CM_ "AUTOGENERATED FILE, DO NOT EDIT";

CM_ "Imported file _honda_common.dbc starts here";
BO_ 304 GAS_PEDAL_2: 8 PCM
 SG_ ENGINE_TORQUE_ESTIMATE : 7|16@0- (1,0) [-1000|1000] "Nm" EON
 SG_ ENGINE_TORQUE_REQUEST : 23|16@0- (1,0) [-1000|1000] "Nm" EON
 SG_ CAR_GAS : 39|8@0+ (1,0) [0|255] "" EON
 SG_ COUNTER : 61|2@0+ (1,0) [0|3] "" EON
 SG_ CHECKSUM : 59|4@0+ (1,0) [0|15] "" EON

BO_ 316 GAS_PEDAL: 8 PCM
 SG_ CAR_GAS : 39|8@0+ (1,0) [0|255] "" EON
 SG_ COUNTER : 61|2@0+ (1,0) [0|3] "" EON
 SG_ CHECKSUM : 59|4@0+ (1,0) [0|15] "" EON

BO_ 344 ENGINE_DATA: 8 PCM
 SG_ XMISSION_SPEED : 7|16@0+ (0.01,0) [0|250] "kph" EON
 SG_ ENGINE_RPM : 23|16@0+ (1,0) [0|15000] "rpm" EON
 SG_ XMISSION_SPEED2 : 39|16@0+ (0.01,0) [0|250] "kph" EON
 SG_ ODOMETER : 55|8@0+ (10,0) [0|2550] "m" XXX
 SG_ COUNTER : 61|2@0+ (1,0) [0|3] "" EON
 SG_ CHECKSUM : 59|4@0+ (1,0) [0|15] "" EON

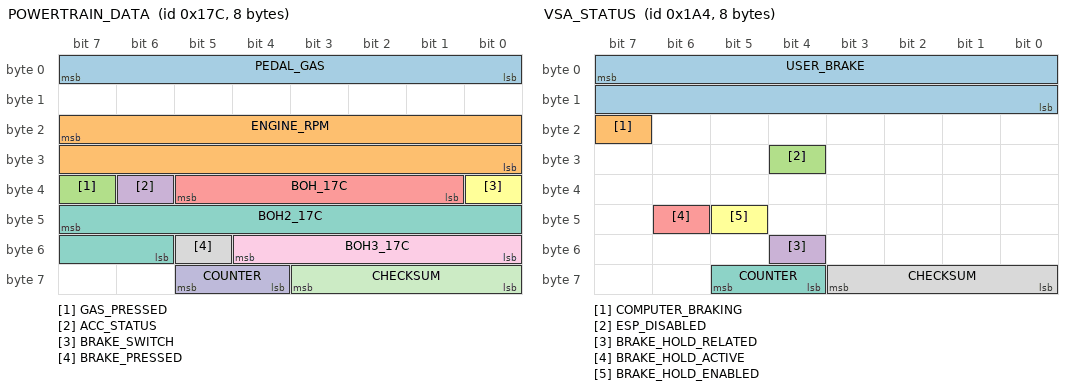
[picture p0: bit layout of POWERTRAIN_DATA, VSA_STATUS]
BO_ 380 POWERTRAIN_DATA: 8 PCM
 SG_ PEDAL_GAS : 7|8@0+ (1,0) [0|255] "" EON
 SG_ ENGINE_RPM : 23|16@0+ (1,0) [0|15000] "rpm" EON
 SG_ GAS_PRESSED : 39|1@0+ (1,0) [0|1] "" EON
 SG_ ACC_STATUS : 38|1@0+ (1,0) [0|1] "" EON
 SG_ BOH_17C : 37|5@0+ (1,0) [0|1] "" EON
 SG_ BRAKE_SWITCH : 32|1@0+ (1,0) [0|1] "" EON
 SG_ BOH2_17C : 47|10@0+ (1,0) [0|1] "" EON
 SG_ BRAKE_PRESSED : 53|1@0+ (1,0) [0|1] "" EON
 SG_ BOH3_17C : 52|5@0+ (1,0) [0|1] "" EON
 SG_ COUNTER : 61|2@0+ (1,0) [0|3] "" EON
 SG_ CHECKSUM : 59|4@0+ (1,0) [0|15] "" EON

BO_ 420 VSA_STATUS: 8 VSA
 SG_ USER_BRAKE : 7|16@0+ (0.015625,-1.609375) [0|1000] "" EON
 SG_ COMPUTER_BRAKING : 23|1@0+ (1,0) [0|1] "" EON
 SG_ ESP_DISABLED : 28|1@0+ (1,0) [0|1] "" EON
 SG_ BRAKE_HOLD_RELATED : 52|1@0+ (1,0) [0|1] "" XXX
 SG_ BRAKE_HOLD_ACTIVE : 46|1@0+ (1,0) [0|1] "" EON
 SG_ BRAKE_HOLD_ENABLED : 45|1@0+ (1,0) [0|1] "" EON
 SG_ COUNTER : 61|2@0+ (1,0) [0|3] "" EON
 SG_ CHECKSUM : 59|4@0+ (1,0) [0|15] "" EON

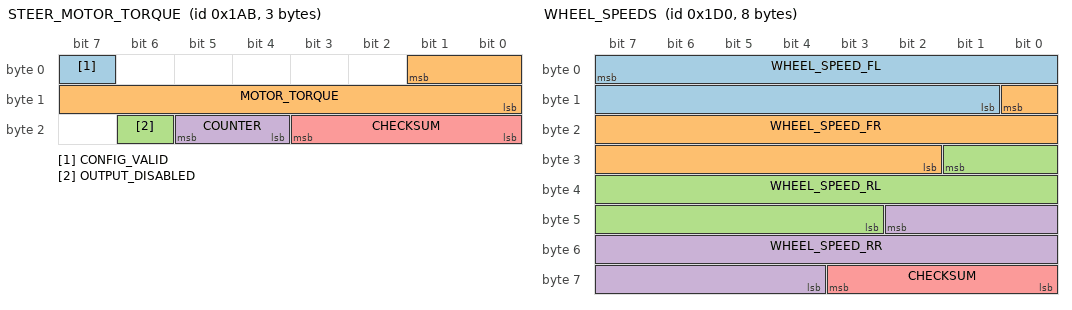
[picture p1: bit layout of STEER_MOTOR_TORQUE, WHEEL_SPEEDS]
BO_ 427 STEER_MOTOR_TORQUE: 3 EPS
 SG_ CONFIG_VALID : 7|1@0+ (1,0) [0|1] "" EON
 SG_ MOTOR_TORQUE : 1|10@0+ (1,0) [0|256] "" EON
 SG_ OUTPUT_DISABLED : 22|1@0+ (1,0) [0|1] "" EON
 SG_ COUNTER : 21|2@0+ (1,0) [0|3] "" EON
 SG_ CHECKSUM : 19|4@0+ (1,0) [0|15] "" EON

BO_ 464 WHEEL_SPEEDS: 8 VSA
 SG_ WHEEL_SPEED_FL : 7|15@0+ (0.01,0) [0|250] "kph" EON
 SG_ WHEEL_SPEED_FR : 8|15@0+ (0.01,0) [0|250] "kph" EON
 SG_ WHEEL_SPEED_RL : 25|15@0+ (0.01,0) [0|250] "kph" EON
 SG_ WHEEL_SPEED_RR : 42|15@0+ (0.01,0) [0|250] "kph" EON
 SG_ CHECKSUM : 59|4@0+ (1,0) [0|3] "" EON

BO_ 490 VEHICLE_DYNAMICS: 8 VSA
 SG_ LAT_ACCEL : 7|16@0- (0.0015,0) [-20|20] "m/s2" EON
 SG_ LONG_ACCEL : 23|16@0- (0.0015,0) [-20|20] "m/s2" EON
 SG_ COUNTER : 61|2@0+ (1,0) [0|3] "" EON
 SG_ CHECKSUM : 59|4@0+ (1,0) [0|3] "" EON

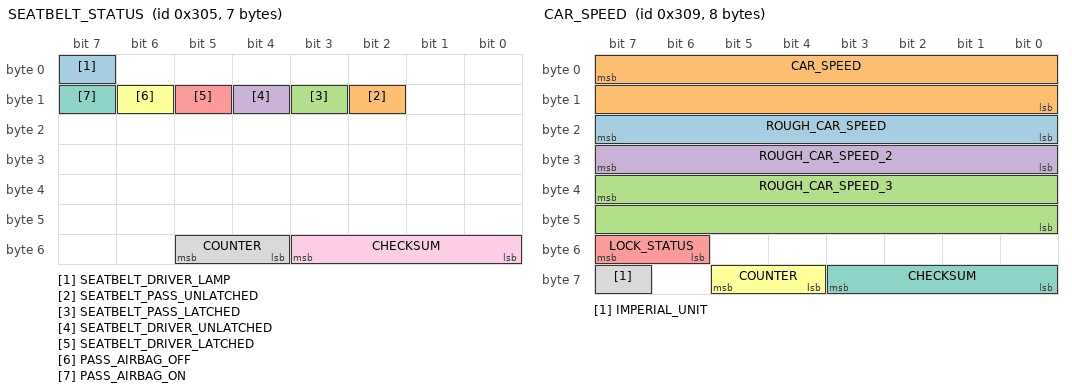
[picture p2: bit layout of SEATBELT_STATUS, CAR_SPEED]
BO_ 773 SEATBELT_STATUS: 7 BDY
 SG_ SEATBELT_DRIVER_LAMP : 7|1@0+ (1,0) [0|1] "" EON
 SG_ SEATBELT_PASS_UNLATCHED : 10|1@0+ (1,0) [0|1] "" EON
 SG_ SEATBELT_PASS_LATCHED : 11|1@0+ (1,0) [0|1] "" EON
 SG_ SEATBELT_DRIVER_UNLATCHED : 12|1@0+ (1,0) [0|1] "" EON
 SG_ SEATBELT_DRIVER_LATCHED : 13|1@0+ (1,0) [0|1] "" EON
 SG_ PASS_AIRBAG_OFF : 14|1@0+ (1,0) [0|1] "" EON
 SG_ PASS_AIRBAG_ON : 15|1@0+ (1,0) [0|1] "" EON
 SG_ COUNTER : 53|2@0+ (1,0) [0|3] "" EON
 SG_ CHECKSUM : 51|4@0+ (1,0) [0|3] "" EON

BO_ 777 CAR_SPEED: 8 PCM
 SG_ ROUGH_CAR_SPEED : 23|8@0+ (1,0) [0|255] "mph" XXX
 SG_ CAR_SPEED : 7|16@0+ (0.01,0) [0|65535] "kph" XXX
 SG_ ROUGH_CAR_SPEED_3 : 39|16@0+ (0.01,0) [0|65535] "kph" XXX
 SG_ ROUGH_CAR_SPEED_2 : 31|8@0+ (1,0) [0|255] "mph" XXX
 SG_ LOCK_STATUS : 55|2@0+ (1,0) [0|255] "" XXX
 SG_ COUNTER : 61|2@0+ (1,0) [0|3] "" XXX
 SG_ CHECKSUM : 59|4@0+ (1,0) [0|15] "" XXX
 SG_ IMPERIAL_UNIT : 63|1@0+ (1,0) [0|1] "" XXX

BO_ 780 ACC_HUD: 8 ADAS
 SG_ PCM_SPEED : 7|16@0+ (0.01,0) [0|250] "kph" BDY
 SG_ PCM_GAS : 23|8@0+ (1,0) [0|127] "" BDY
 SG_ CRUISE_SPEED : 31|8@0+ (1,0) [0|255] "kph" BDY
 SG_ DTC_MODE : 39|1@0+ (1,0) [0|1] "" BDY
 SG_ BOH : 38|1@0+ (1,0) [0|1] "" BDY
 SG_ ACC_PROBLEM : 37|1@0+ (1,0) [0|1] "" BDY
 SG_ FCM_OFF : 35|1@0+ (1,0) [0|1] "" BDY
 SG_ FCM_OFF_2 : 36|1@0+ (1,0) [0|1] "" BDY
 SG_ FCM_PROBLEM : 34|1@0+ (1,0) [0|1] "" BDY
 SG_ RADAR_OBSTRUCTED : 33|1@0+ (1,0) [0|1] "" BDY
 SG_ ENABLE_MINI_CAR : 32|1@0+ (1,0) [0|1] "" BDY
 SG_ HUD_DISTANCE : 47|2@0+ (1,0) [0|3] "" BDY
 SG_ HUD_LEAD : 45|2@0+ (1,0) [0|3] "" BDY
 SG_ BOH_3 : 43|1@0+ (1,0) [0|3] "" BDY
 SG_ BOH_4 : 42|1@0+ (1,0) [0|3] "" BDY
 SG_ BOH_5 : 41|1@0+ (1,0) [0|3] "" BDY
 SG_ CRUISE_CONTROL_LABEL : 40|1@0+ (1,0) [0|3] "" BDY
 SG_ SET_ME_X01_2 : 55|1@0+ (1,0) [0|1] "" BDY
 SG_ IMPERIAL_UNIT : 54|1@0+ (1,0) [0|1] "" BDY
 SG_ ACC_ON : 52|1@0+ (1,0) [0|1] "" BDY
 SG_ CHIME : 51|3@0+ (1,0) [0|1] "" BDY
 SG_ SET_ME_X01 : 48|1@0+ (1,0) [0|1] "" BDY
 SG_ ICONS : 63|2@0+ (1,0) [0|1] "" BDY
 SG_ COUNTER : 61|2@0+ (1,0) [0|3] "" BDY
 SG_ CHECKSUM : 59|4@0+ (1,0) [0|3] "" BDY

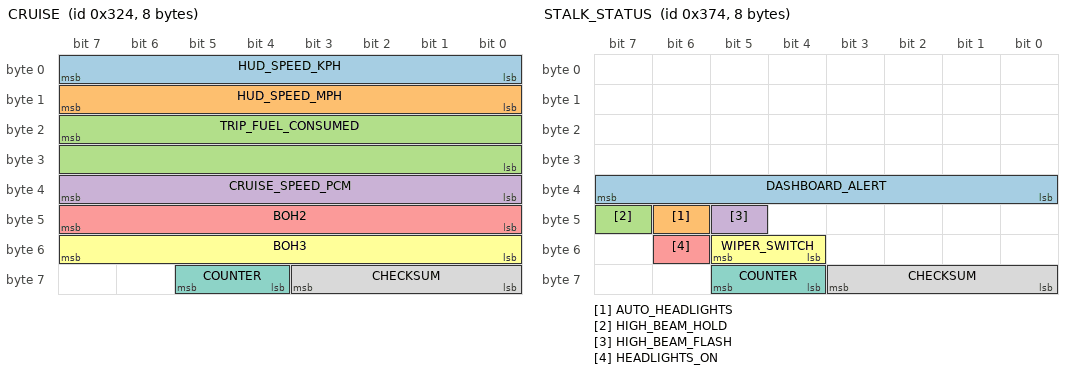
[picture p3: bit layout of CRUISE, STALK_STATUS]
BO_ 804 CRUISE: 8 PCM
 SG_ HUD_SPEED_KPH : 7|8@0+ (1,0) [0|255] "kph" EON
 SG_ HUD_SPEED_MPH : 15|8@0+ (1,0) [0|255] "mph" EON
 SG_ TRIP_FUEL_CONSUMED : 23|16@0+ (1,0) [0|255] "" EON
 SG_ CRUISE_SPEED_PCM : 39|8@0+ (1,0) [0|255] "" EON
 SG_ BOH2 : 47|8@0- (1,0) [0|255] "" EON
 SG_ BOH3 : 55|8@0+ (1,0) [0|255] "" EON
 SG_ COUNTER : 61|2@0+ (1,0) [0|3] "" EON
 SG_ CHECKSUM : 59|4@0+ (1,0) [0|15] "" EON

BO_ 884 STALK_STATUS: 8 XXX
 SG_ DASHBOARD_ALERT : 39|8@0+ (1,0) [0|255] "" EON
 SG_ AUTO_HEADLIGHTS : 46|1@0+ (1,0) [0|1] "" EON
 SG_ HIGH_BEAM_HOLD : 47|1@0+ (1,0) [0|1] "" EON
 SG_ HIGH_BEAM_FLASH : 45|1@0+ (1,0) [0|1] "" EON
 SG_ HEADLIGHTS_ON : 54|1@0+ (1,0) [0|1] "" EON
 SG_ WIPER_SWITCH : 53|2@0+ (1,0) [0|3] "" XXX
 SG_ COUNTER : 61|2@0+ (1,0) [0|3] "" EON
 SG_ CHECKSUM : 59|4@0+ (1,0) [0|15] "" EON

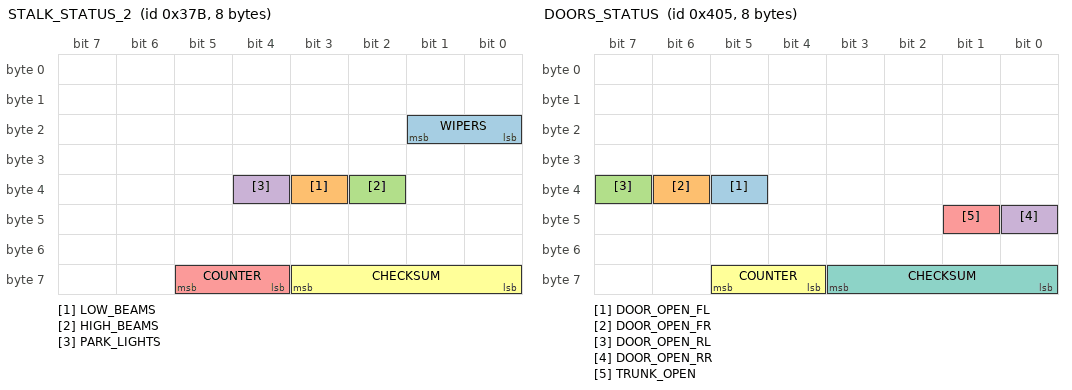
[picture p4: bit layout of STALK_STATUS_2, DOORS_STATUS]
BO_ 891 STALK_STATUS_2: 8 XXX
 SG_ WIPERS : 17|2@0+ (1,0) [0|3] "" EON
 SG_ LOW_BEAMS : 35|1@0+ (1,0) [0|1] "" XXX
 SG_ HIGH_BEAMS : 34|1@0+ (1,0) [0|1] "" XXX
 SG_ PARK_LIGHTS : 36|1@0+ (1,0) [0|1] "" XXX
 SG_ COUNTER : 61|2@0+ (1,0) [0|3] "" EON
 SG_ CHECKSUM : 59|4@0+ (1,0) [0|15] "" EON

BO_ 1029 DOORS_STATUS: 8 BDY
 SG_ DOOR_OPEN_FL : 37|1@0+ (1,0) [0|1] "" EON
 SG_ DOOR_OPEN_FR : 38|1@0+ (1,0) [0|1] "" EON
 SG_ DOOR_OPEN_RL : 39|1@0+ (1,0) [0|1] "" EON
 SG_ DOOR_OPEN_RR : 40|1@0+ (1,0) [0|1] "" EON
 SG_ TRUNK_OPEN : 41|1@0+ (1,0) [0|1] "" EON
 SG_ COUNTER : 61|2@0+ (1,0) [0|3] "" EON
 SG_ CHECKSUM : 59|4@0+ (1,0) [0|15] "" EON

CM_ SG_ 304 "Seems to be platform-agnostic";
CM_ SG_ 316 "Should exist on Nidec";
CM_ SG_ 420 BRAKE_HOLD_RELATED "On when Brake Hold engaged";
CM_ SG_ 490 LONG_ACCEL "wheel speed derivative, noisy and zero snapping";
CM_ SG_ 773 PASS_AIRBAG_ON "Might just be indicator light";
CM_ SG_ 773 PASS_AIRBAG_OFF "Might just be indicator light";
CM_ SG_ 780 CRUISE_SPEED "255 = no speed";
CM_ SG_ 780 PCM_SPEED "Used by Nidec";
CM_ SG_ 780 PCM_GAS "Used by Nidec";
CM_ SG_ 804 CRUISE_SPEED_PCM "255 = no speed";

VAL_ 780 CRUISE_SPEED 255 "no_speed" 252 "stopped";
VAL_ 780 HUD_LEAD 3 "acc_off" 2 "solid_car" 1 "dashed_car" 0 "no_car";
VAL_ 884 DASHBOARD_ALERT 0 "none" 51 "acc_problem" 55 "cmbs_problem" 75 "key_not_detected" 79 "fasten_seatbelt" 111 "lkas_problem" 131 "brake_system_problem" 132 "brake_hold_problem" 139 "tbd" 161 "door_open";
VAL_ 891 WIPERS 4 "High" 2 "Low" 0 "Off";

CM_ "Imported file _bosch_2018.dbc starts here";
BO_ 148 KINEMATICS: 8 XXX
 SG_ LAT_ACCEL : 7|10@0+ (-0.035,17.92) [-20|20] "m/s2" EON
 SG_ LONG_ACCEL : 25|10@0+ (-0.035,17.92) [-20|20] "m/s2" EON
 SG_ CHECKSUM : 59|4@0+ (1,0) [0|3] "" EON
 SG_ COUNTER : 61|2@0+ (1,0) [0|3] "" EON

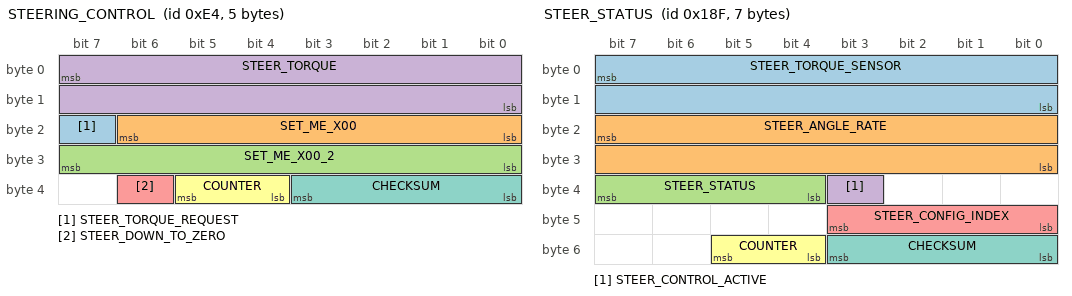
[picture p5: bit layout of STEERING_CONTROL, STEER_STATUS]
BO_ 228 STEERING_CONTROL: 5 EON
 SG_ STEER_TORQUE_REQUEST : 23|1@0+ (1,0) [0|1] "" EPS
 SG_ SET_ME_X00 : 22|7@0+ (1,0) [0|127] "" EPS
 SG_ SET_ME_X00_2 : 31|8@0+ (1,0) [0|0] "" EPS
 SG_ STEER_TORQUE : 7|16@0- (1,0) [-4096|4096] "" EPS
 SG_ STEER_DOWN_TO_ZERO : 38|1@0+ (1,0) [0|1] "" EPS
 SG_ COUNTER : 37|2@0+ (1,0) [0|3] "" EPS
 SG_ CHECKSUM : 35|4@0+ (1,0) [0|15] "" EPS

BO_ 229 BOSCH_SUPPLEMENTAL_1: 8 XXX
 SG_ SET_ME_X04 : 0|8@1+ (1,0) [0|255] "" XXX
 SG_ SET_ME_X00 : 8|8@1+ (1,0) [0|255] "" XXX
 SG_ SET_ME_X80 : 16|8@1+ (1,0) [0|255] "" XXX
 SG_ SET_ME_X10 : 24|8@1+ (1,0) [0|255] "" XXX
 SG_ COUNTER : 61|2@0+ (1,0) [0|3] "" XXX
 SG_ CHECKSUM : 59|4@0+ (1,0) [0|15] "" XXX

BO_ 232 BRAKE_HOLD: 7 XXX
 SG_ XMISSION_SPEED : 7|14@0- (1,0) [1|0] "" XXX
 SG_ COMPUTER_BRAKE : 39|16@0+ (1,0) [0|0] "" XXX
 SG_ COMPUTER_BRAKE_REQUEST : 29|1@0+ (1,0) [0|0] "" XXX
 SG_ COUNTER : 53|2@0+ (1,0) [0|3] "" XXX
 SG_ CHECKSUM : 51|4@0+ (1,0) [0|15] "" XXX

BO_ 399 STEER_STATUS: 7 EPS
 SG_ STEER_TORQUE_SENSOR : 7|16@0- (-1,0) [-31000|31000] "tbd" EON
 SG_ STEER_ANGLE_RATE : 23|16@0- (-0.1,0) [-31000|31000] "deg/s" EON
 SG_ STEER_STATUS : 39|4@0+ (1,0) [0|15] "" EON
 SG_ STEER_CONTROL_ACTIVE : 35|1@0+ (1,0) [0|1] "" EON
 SG_ STEER_CONFIG_INDEX : 43|4@0+ (1,0) [0|15] "" EON
 SG_ COUNTER : 53|2@0+ (1,0) [0|3] "" EON
 SG_ CHECKSUM : 51|4@0+ (1,0) [0|15] "" EON

BO_ 450 EPB_STATUS: 8 EPB
 SG_ EPB_ACTIVE : 3|1@0+ (1,0) [0|1] "" EON
 SG_ EPB_STATE : 29|2@0+ (1,0) [0|3] "" EON
 SG_ COUNTER : 61|2@0+ (1,0) [0|3] "" XXX
 SG_ CHECKSUM : 59|4@0+ (1,0) [0|15] "" XXX

BO_ 545 XXX_16: 6 SCM
 SG_ ECON_ON : 23|1@0+ (1,0) [0|1] "" XXX
 SG_ DRIVE_MODE : 37|2@0+ (1,0) [0|3] "" XXX
 SG_ COUNTER : 45|2@0+ (1,0) [0|3] "" BDY
 SG_ CHECKSUM : 43|4@0+ (1,0) [0|15] "" BDY

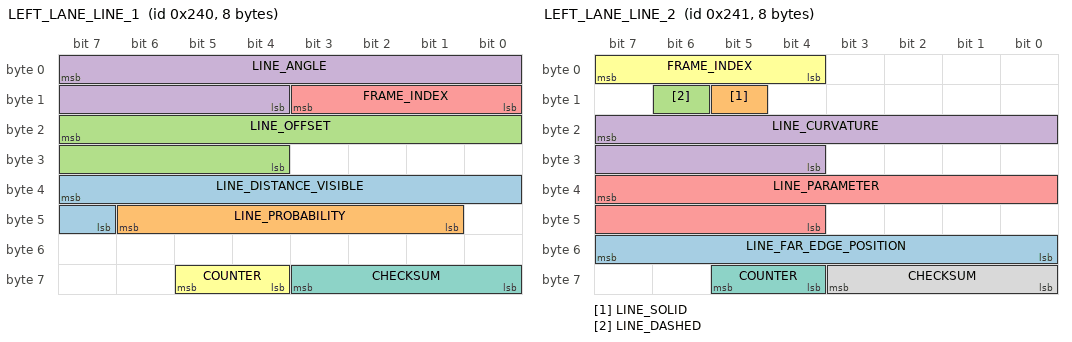
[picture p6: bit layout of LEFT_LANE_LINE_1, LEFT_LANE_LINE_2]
BO_ 576 LEFT_LANE_LINE_1: 8 CAM
 SG_ LINE_DISTANCE_VISIBLE : 39|9@0+ (1,0) [0|1] "" XXX
 SG_ LINE_PROBABILITY : 46|6@0+ (0.015625,0) [0|1] "" XXX
 SG_ LINE_OFFSET : 23|12@0+ (0.004,-8.192) [0|1] "Meters" XXX
 SG_ LINE_ANGLE : 7|12@0+ (0.0005,-1.024) [0|1] "" XXX
 SG_ FRAME_INDEX : 8|4@1+ (1,0) [0|15] "" XXX
 SG_ COUNTER : 61|2@0+ (1,0) [0|1] "" XXX
 SG_ CHECKSUM : 59|4@0+ (1,0) [0|1] "" XXX

BO_ 577 LEFT_LANE_LINE_2: 8 CAM
 SG_ LINE_FAR_EDGE_POSITION : 55|8@0+ (1,-128) [0|1] "" XXX
 SG_ LINE_SOLID : 13|1@0+ (1,0) [0|1] "" XXX
 SG_ LINE_DASHED : 14|1@0+ (1,0) [0|1] "" XXX
 SG_ LINE_CURVATURE : 23|12@0+ (0.00001,-0.02048) [0|1] "" XXX
 SG_ LINE_PARAMETER : 39|12@0+ (1,0) [0|1] "" XXX
 SG_ FRAME_INDEX : 7|4@0+ (1,0) [0|15] "" XXX
 SG_ COUNTER : 61|2@0+ (1,0) [0|1] "" XXX
 SG_ CHECKSUM : 59|4@0+ (1,0) [0|1] "" XXX

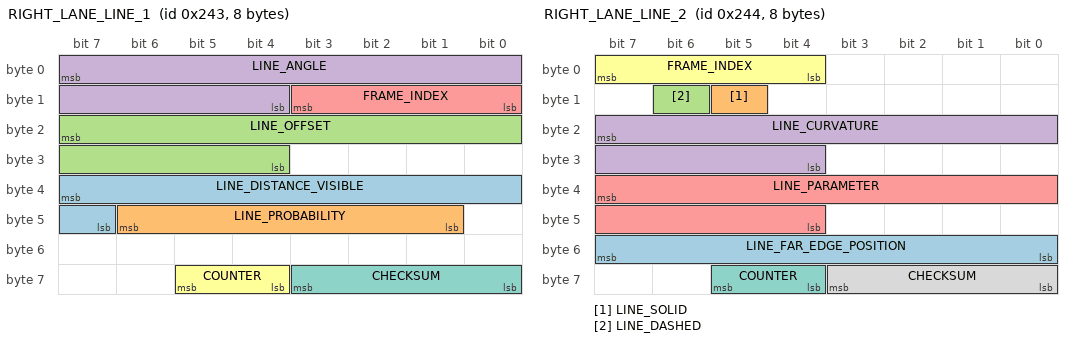
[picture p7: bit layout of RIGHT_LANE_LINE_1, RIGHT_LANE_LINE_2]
BO_ 579 RIGHT_LANE_LINE_1: 8 CAM
 SG_ LINE_DISTANCE_VISIBLE : 39|9@0+ (1,0) [0|1] "" XXX
 SG_ LINE_PROBABILITY : 46|6@0+ (0.015625,0) [0|1] "" XXX
 SG_ LINE_OFFSET : 23|12@0+ (0.004,-8.192) [0|1] "Meters" XXX
 SG_ LINE_ANGLE : 7|12@0+ (0.0005,-1.024) [0|1] "" XXX
 SG_ FRAME_INDEX : 8|4@1+ (1,0) [0|15] "" XXX
 SG_ COUNTER : 61|2@0+ (1,0) [0|1] "" XXX
 SG_ CHECKSUM : 59|4@0+ (1,0) [0|1] "" XXX

BO_ 580 RIGHT_LANE_LINE_2: 8 CAM
 SG_ LINE_FAR_EDGE_POSITION : 55|8@0+ (1,-128) [0|1] "" XXX
 SG_ LINE_SOLID : 13|1@0+ (1,0) [0|1] "" XXX
 SG_ LINE_DASHED : 14|1@0+ (1,0) [0|1] "" XXX
 SG_ LINE_CURVATURE : 23|12@0+ (0.00001,-0.02048) [0|1] "" XXX
 SG_ LINE_PARAMETER : 39|12@0+ (1,0) [0|1] "" XXX
 SG_ FRAME_INDEX : 7|4@0+ (1,0) [0|15] "" XXX
 SG_ COUNTER : 61|2@0+ (1,0) [0|1] "" XXX
 SG_ CHECKSUM : 59|4@0+ (1,0) [0|1] "" XXX

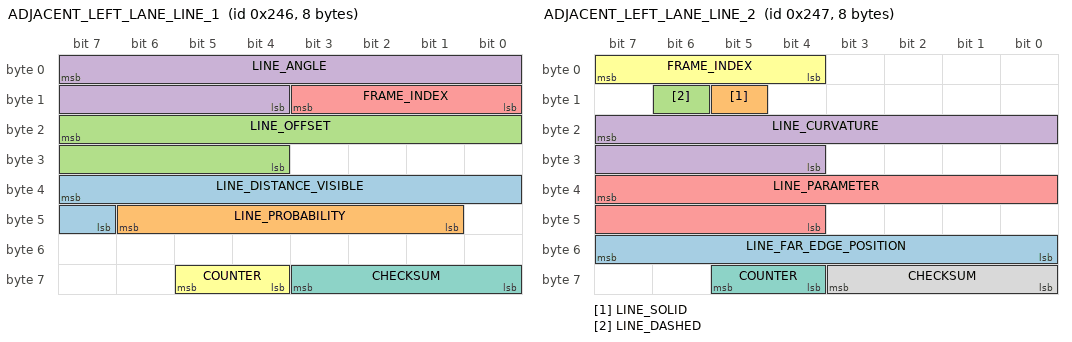
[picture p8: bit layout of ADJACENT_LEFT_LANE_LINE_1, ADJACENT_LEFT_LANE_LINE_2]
BO_ 582 ADJACENT_LEFT_LANE_LINE_1: 8 CAM
 SG_ LINE_DISTANCE_VISIBLE : 39|9@0+ (1,0) [0|1] "" XXX
 SG_ LINE_PROBABILITY : 46|6@0+ (0.015625,0) [0|1] "" XXX
 SG_ LINE_OFFSET : 23|12@0+ (0.004,-8.192) [0|1] "Meters" XXX
 SG_ LINE_ANGLE : 7|12@0+ (0.0005,-1.024) [0|1] "" XXX
 SG_ FRAME_INDEX : 8|4@1+ (1,0) [0|15] "" XXX
 SG_ COUNTER : 61|2@0+ (1,0) [0|1] "" XXX
 SG_ CHECKSUM : 59|4@0+ (1,0) [0|1] "" XXX

BO_ 583 ADJACENT_LEFT_LANE_LINE_2: 8 CAM
 SG_ LINE_FAR_EDGE_POSITION : 55|8@0+ (1,-128) [0|1] "" XXX
 SG_ LINE_SOLID : 13|1@0+ (1,0) [0|1] "" XXX
 SG_ LINE_DASHED : 14|1@0+ (1,0) [0|1] "" XXX
 SG_ LINE_CURVATURE : 23|12@0+ (0.00001,-0.02048) [0|1] "" XXX
 SG_ LINE_PARAMETER : 39|12@0+ (1,0) [0|1] "" XXX
 SG_ FRAME_INDEX : 7|4@0+ (1,0) [0|15] "" XXX
 SG_ COUNTER : 61|2@0+ (1,0) [0|1] "" XXX
 SG_ CHECKSUM : 59|4@0+ (1,0) [0|1] "" XXX

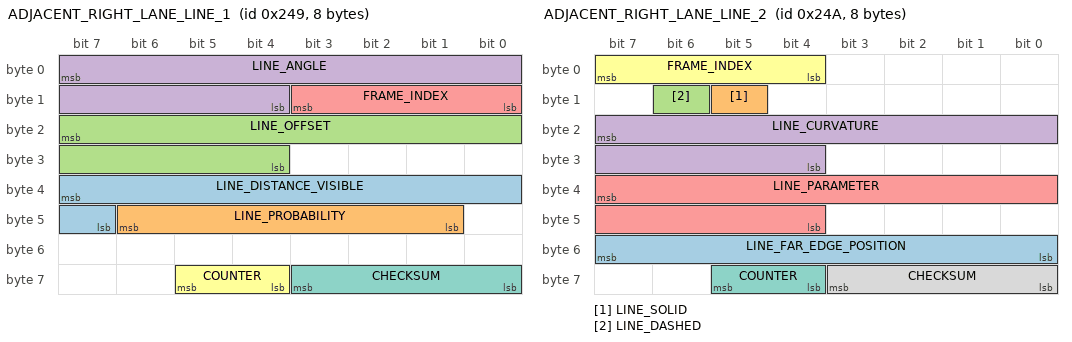
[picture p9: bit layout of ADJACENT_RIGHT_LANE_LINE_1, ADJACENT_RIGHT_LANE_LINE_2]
BO_ 585 ADJACENT_RIGHT_LANE_LINE_1: 8 CAM
 SG_ LINE_DISTANCE_VISIBLE : 39|9@0+ (1,0) [0|1] "" XXX
 SG_ LINE_PROBABILITY : 46|6@0+ (0.015625,0) [0|1] "" XXX
 SG_ LINE_OFFSET : 23|12@0+ (0.004,-8.192) [0|1] "Meters" XXX
 SG_ LINE_ANGLE : 7|12@0+ (0.0005,-1.024) [0|1] "" XXX
 SG_ FRAME_INDEX : 8|4@1+ (1,0) [0|15] "" XXX
 SG_ COUNTER : 61|2@0+ (1,0) [0|1] "" XXX
 SG_ CHECKSUM : 59|4@0+ (1,0) [0|1] "" XXX

BO_ 586 ADJACENT_RIGHT_LANE_LINE_2: 8 CAM
 SG_ LINE_FAR_EDGE_POSITION : 55|8@0+ (1,-128) [0|1] "" XXX
 SG_ LINE_SOLID : 13|1@0+ (1,0) [0|1] "" XXX
 SG_ LINE_DASHED : 14|1@0+ (1,0) [0|1] "" XXX
 SG_ LINE_CURVATURE : 23|12@0+ (0.00001,-0.02048) [0|1] "" XXX
 SG_ LINE_PARAMETER : 39|12@0+ (1,0) [0|1] "" XXX
 SG_ FRAME_INDEX : 7|4@0+ (1,0) [0|15] "" XXX
 SG_ COUNTER : 61|2@0+ (1,0) [0|1] "" XXX
 SG_ CHECKSUM : 59|4@0+ (1,0) [0|1] "" XXX

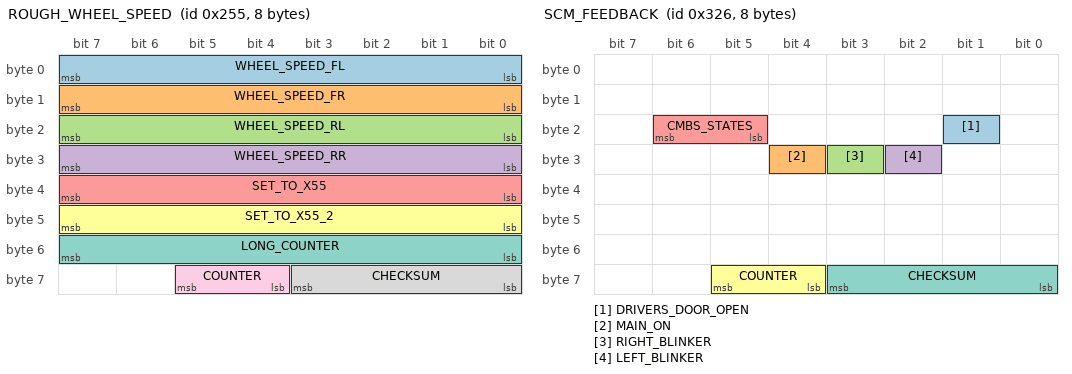
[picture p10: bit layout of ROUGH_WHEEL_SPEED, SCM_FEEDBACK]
BO_ 597 ROUGH_WHEEL_SPEED: 8 VSA
 SG_ WHEEL_SPEED_FL : 7|8@0+ (1,0) [0|255] "mph" EON
 SG_ WHEEL_SPEED_FR : 15|8@0+ (1,0) [0|255] "mph" EON
 SG_ WHEEL_SPEED_RL : 23|8@0+ (1,0) [0|255] "mph" EON
 SG_ WHEEL_SPEED_RR : 31|8@0+ (1,0) [0|255] "mph" EON
 SG_ SET_TO_X55 : 39|8@0+ (1,0) [0|255] "" XXX
 SG_ SET_TO_X55_2 : 47|8@0+ (1,0) [0|255] "" EON
 SG_ LONG_COUNTER : 55|8@0+ (1,0) [0|255] "" XXX
 SG_ CHECKSUM : 59|4@0+ (1,0) [0|15] "" XXX
 SG_ COUNTER : 61|2@0+ (1,0) [0|3] "" XXX

BO_ 662 SCM_BUTTONS: 4 SCM
 SG_ CRUISE_BUTTONS : 7|3@0+ (1,0) [0|7] "" EON
 SG_ CRUISE_SETTING : 3|2@0+ (1,0) [0|3] "" EON
 SG_ COUNTER : 29|2@0+ (1,0) [0|3] "" EON
 SG_ CHECKSUM : 27|4@0+ (1,0) [0|15] "" EON

BO_ 806 SCM_FEEDBACK: 8 SCM
 SG_ DRIVERS_DOOR_OPEN : 17|1@0+ (1,0) [0|1] "" XXX
 SG_ MAIN_ON : 28|1@0+ (1,0) [0|1] "" EON
 SG_ RIGHT_BLINKER : 27|1@0+ (1,0) [0|1] "" EON
 SG_ LEFT_BLINKER : 26|1@0+ (1,0) [0|1] "" EON
 SG_ CMBS_STATES : 22|2@0+ (1,0) [0|3] "" EON
 SG_ COUNTER : 61|2@0+ (1,0) [0|3] "" XXX
 SG_ CHECKSUM : 59|4@0+ (1,0) [0|15] "" XXX

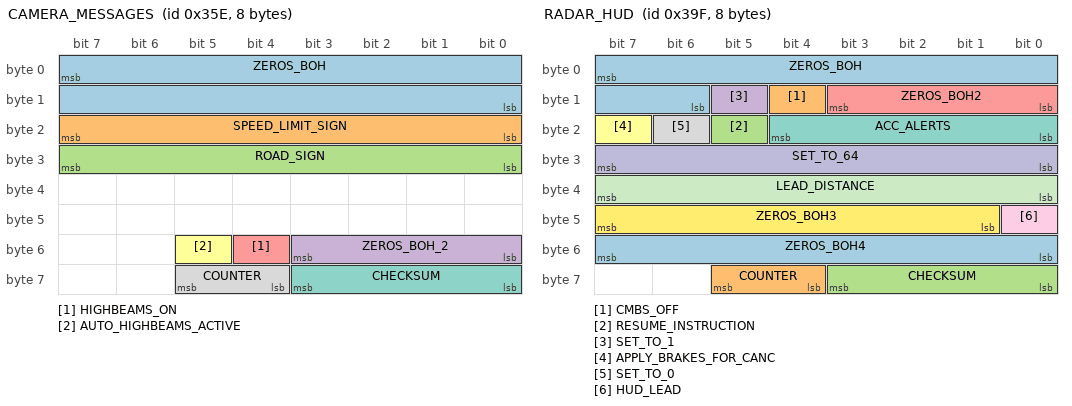
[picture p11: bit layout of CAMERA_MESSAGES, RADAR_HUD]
BO_ 862 CAMERA_MESSAGES: 8 CAM
 SG_ ZEROS_BOH : 7|16@0+ (1,0) [0|127] "" BDY
 SG_ SPEED_LIMIT_SIGN : 23|8@0+ (1,0) [0|255] "" XXX
 SG_ ROAD_SIGN : 31|8@0+ (1,0) [0|255] "" XXX
 SG_ ZEROS_BOH_2 : 51|4@0+ (1,0) [0|15] "" XXX
 SG_ HIGHBEAMS_ON : 52|1@0+ (1,0) [0|1] "" XXX
 SG_ AUTO_HIGHBEAMS_ACTIVE : 53|1@0+ (1,0) [0|1] "" XXX
 SG_ CHECKSUM : 59|4@0+ (1,0) [0|15] "" XXX
 SG_ COUNTER : 61|2@0+ (1,0) [0|3] "" XXX

BO_ 927 RADAR_HUD: 8 RADAR
 SG_ ZEROS_BOH : 7|10@0+ (1,0) [0|127] "" BDY
 SG_ CMBS_OFF : 12|1@0+ (1,0) [0|1] "" BDY
 SG_ RESUME_INSTRUCTION : 21|1@0+ (1,0) [0|1] "" XXX
 SG_ SET_TO_1 : 13|1@0+ (1,0) [0|1] "" BDY
 SG_ ZEROS_BOH2 : 11|4@0+ (1,0) [0|1] "" XXX
 SG_ APPLY_BRAKES_FOR_CANC : 23|1@0+ (1,0) [0|1] "" XXX
 SG_ ACC_ALERTS : 20|5@0+ (1,0) [0|1] "" BDY
 SG_ SET_TO_0 : 22|1@0+ (1,0) [0|1] "" XXX
 SG_ HUD_LEAD : 40|1@0+ (1,0) [0|1] "" XXX
 SG_ SET_TO_64 : 31|8@0+ (1,0) [0|255] "" XXX
 SG_ LEAD_DISTANCE : 39|8@0+ (1,0) [0|255] "" XXX
 SG_ ZEROS_BOH3 : 47|7@0+ (1,0) [0|127] "" XXX
 SG_ ZEROS_BOH4 : 55|8@0+ (1,0) [0|255] "" XXX
 SG_ COUNTER : 61|2@0+ (1,0) [0|3] "" XXX
 SG_ CHECKSUM : 59|4@0+ (1,0) [0|15] "" XXX

BO_ 13274 LKAS_HUD_A: 5 ADAS
 SG_ CAM_TEMP_HIGH : 7|1@0+ (1,0) [0|255] "" BDY
 SG_ SET_ME_X41 : 6|7@0+ (1,0) [0|127] "" BDY
 SG_ BOH : 6|7@0+ (1,0) [0|127] "" BDY
 SG_ DASHED_LANES : 14|1@0+ (1,0) [0|1] "" BDY
 SG_ DTC : 13|1@0+ (1,0) [0|1] "" BDY
 SG_ LKAS_PROBLEM : 12|1@0+ (1,0) [0|1] "" BDY
 SG_ LKAS_OFF : 11|1@0+ (1,0) [0|1] "" BDY
 SG_ SOLID_LANES : 10|1@0+ (1,0) [0|1] "" BDY
 SG_ LANE_DEPARTURE_WARNING : 9|1@0+ (1,0) [0|0] "" XXX
 SG_ RDM_OFF_MINI_ICON : 22|1@0+ (1,0) [0|0] "" XXX
 SG_ STEERING_REQUIRED : 8|1@0+ (1,0) [0|1] "" BDY
 SG_ BOH_2 : 23|2@0+ (1,0) [0|4] "" BDY
 SG_ LDW_PROBLEM : 21|1@0+ (1,0) [0|1] "" BDY
 SG_ BEEP : 17|2@0+ (1,0) [0|1] "" BDY
 SG_ SET_ME_X01 : 20|1@0+ (1,0) [0|1] "" BDY
 SG_ LDW_ON : 28|1@0+ (1,0) [0|1] "" BDY
 SG_ LDW_OFF : 27|1@0+ (1,0) [0|1] "" BDY
 SG_ CLEAN_WINDSHIELD : 26|1@0+ (1,0) [0|1] "" BDY
 SG_ COUNTER : 37|2@0+ (1,0) [0|3] "" BDY
 SG_ CHECKSUM : 35|4@0+ (1,0) [0|15] "" BDY

BO_ 13275 LKAS_HUD_B: 8 ADAS
 SG_ CAM_TEMP_HIGH : 7|1@0+ (1,0) [0|255] "" BDY
 SG_ SET_ME_X41 : 6|7@0+ (1,0) [0|127] "" BDY
 SG_ BOH : 6|7@0+ (1,0) [0|127] "" BDY
 SG_ DASHED_LANES : 14|1@0+ (1,0) [0|1] "" BDY
 SG_ DTC : 13|1@0+ (1,0) [0|1] "" BDY
 SG_ LKAS_PROBLEM : 12|1@0+ (1,0) [0|1] "" BDY
 SG_ LKAS_OFF : 11|1@0+ (1,0) [0|1] "" BDY
 SG_ SOLID_LANES : 10|1@0+ (1,0) [0|1] "" BDY
 SG_ LANE_DEPARTURE_WARNING : 9|1@0+ (1,0) [0|0] "" XXX
 SG_ RDM_OFF_MINI_ICON : 22|1@0+ (1,0) [0|0] "" XXX
 SG_ STEERING_REQUIRED : 8|1@0+ (1,0) [0|1] "" BDY
 SG_ BOH_2 : 23|2@0+ (1,0) [0|4] "" BDY
 SG_ LDW_PROBLEM : 21|1@0+ (1,0) [0|1] "" BDY
 SG_ BEEP : 17|2@0+ (1,0) [0|1] "" BDY
 SG_ SET_ME_X01 : 20|1@0+ (1,0) [0|1] "" BDY
 SG_ LDW_ON : 28|1@0+ (1,0) [0|1] "" BDY
 SG_ LDW_OFF : 27|1@0+ (1,0) [0|1] "" BDY
 SG_ CLEAN_WINDSHIELD : 26|1@0+ (1,0) [0|1] "" BDY
 SG_ COUNTER : 61|2@0+ (1,0) [0|3] "" BDY
 SG_ CHECKSUM : 59|4@0+ (1,0) [0|15] "" BDY

CM_ SG_ 450 EPB_STATE "3: On, 2: Disengaging, 1: Engaging, 0: Off";
CM_ SG_ 576 LINE_DISTANCE_VISIBLE "Length of line visible, undecoded";
CM_ SG_ 577 LINE_FAR_EDGE_POSITION "Appears to be a measure of line thickness, indicates location of the portion of the line furthest from the car, undecoded";
CM_ SG_ 577 LINE_PARAMETER "Unclear if this is low quality line curvature rate or if this is something else, but it is correlated with line curvature, undecoded";
CM_ SG_ 577 LINE_DASHED "1 = line is dashed";
CM_ SG_ 577 LINE_SOLID "1 = line is solid";

VAL_ 399 STEER_STATUS 6 "tmp_fault" 5 "fault_1" 4 "no_torque_alert_2" 3 "low_speed_lockout" 2 "no_torque_alert_1" 0 "normal";
VAL_ 862 SPEED_LIMIT_SIGN 97 "SPEED_LIMIT_5" 98 "SPEED_LIMIT_10" 99 "SPEED_LIMIT_15" 100 "SPEED_LIMIT_20" 101 "SPEED_LIMIT_25" 102 "SPEED_LIMIT_30" 103 "SPEED_LIMIT_35" 104 "SPEED_LIMIT_40" 105 "SPEED_LIMIT_45" 106 "SPEED_LIMIT_50" 107 "SPEED_LIMIT_55" 108 "SPEED_LIMIT_60" 109 "SPEED_LIMIT_65" 110 "SPEED_LIMIT_70" 111 "SPEED_LIMIT_75" 112 "SPEED_LIMIT_80" 113 "SPEED_LIMIT_85" 125 "SPEED_LIMIT_NA" 0 "STOP_SIGN";
VAL_ 862 ROAD_SIGN 0 "NO_SIGN" 89 "STOP_SIGN";

CM_ "Imported file _bosch_adas_2018.dbc starts here";
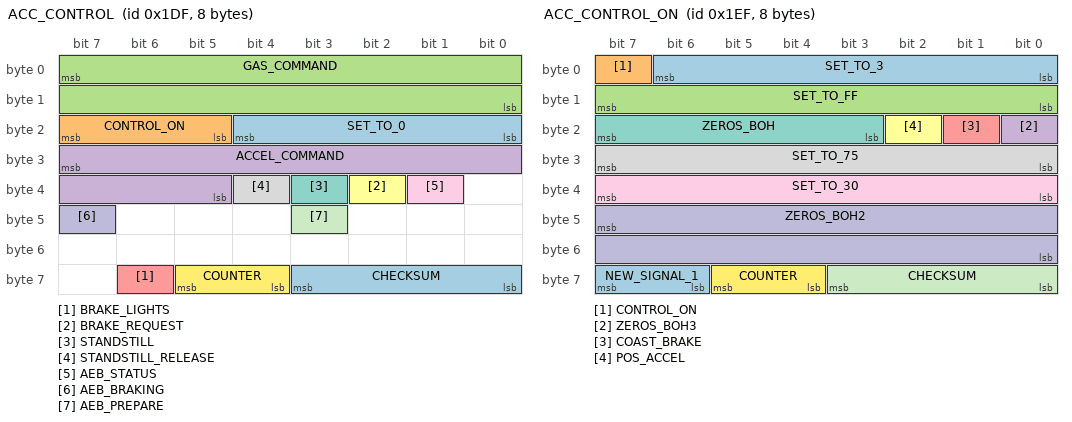
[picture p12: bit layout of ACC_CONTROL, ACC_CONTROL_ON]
BO_ 479 ACC_CONTROL: 8 EON
 SG_ SET_TO_0 : 20|5@0+ (1,0) [0|1] "" XXX
 SG_ CONTROL_ON : 23|3@0+ (1,0) [0|5] "" XXX
 SG_ GAS_COMMAND : 7|16@0- (0.1,0) [0|0] "nM" XXX
 SG_ ACCEL_COMMAND : 31|11@0- (0.01,0) [0|0] "m/s2" XXX
 SG_ BRAKE_LIGHTS : 62|1@0+ (1,0) [0|1] "" XXX
 SG_ BRAKE_REQUEST : 34|1@0+ (1,0) [0|1] "" XXX
 SG_ STANDSTILL : 35|1@0+ (1,0) [0|1] "" XXX
 SG_ STANDSTILL_RELEASE : 36|1@0+ (1,0) [0|1] "" XXX
 SG_ AEB_STATUS : 33|1@0+ (1,0) [0|1] "" XXX
 SG_ AEB_BRAKING : 47|1@0+ (1,0) [0|1] "" XXX
 SG_ AEB_PREPARE : 43|1@0+ (1,0) [0|1] "" XXX
 SG_ COUNTER : 61|2@0+ (1,0) [0|3] "" XXX
 SG_ CHECKSUM : 59|4@0+ (1,0) [0|15] "" XXX

BO_ 495 ACC_CONTROL_ON: 8 XXX
 SG_ SET_TO_3 : 6|7@0+ (1,0) [0|0] "" XXX
 SG_ CONTROL_ON : 7|1@0+ (1,0) [0|0] "" XXX
 SG_ SET_TO_FF : 15|8@0+ (1,0) [0|0] "" XXX
 SG_ ZEROS_BOH3 : 16|1@0+ (1,0) [0|0] "" XXX
 SG_ COAST_BRAKE : 17|1@0+ (1,0) [0|0] "" XXX
 SG_ POS_ACCEL : 18|1@0+ (1,0) [0|0] "" XXX
 SG_ ZEROS_BOH : 23|5@0+ (1,0) [0|0] "" XXX
 SG_ SET_TO_75 : 31|8@0+ (1,0) [0|0] "" XXX
 SG_ SET_TO_30 : 39|8@0+ (1,0) [0|0] "" XXX
 SG_ ZEROS_BOH2 : 47|16@0+ (1,0) [0|0] "" XXX
 SG_ CHECKSUM : 59|4@0+ (1,0) [0|0] "" XXX
 SG_ COUNTER : 61|2@0+ (1,0) [0|0] "" XXX
 SG_ NEW_SIGNAL_1 : 63|2@0+ (1,0) [0|0] "" XXX

BO_ 829 LKAS_HUD: 5 ADAS
 SG_ CAM_TEMP_HIGH : 7|1@0+ (1,0) [0|255] "" BDY
 SG_ SET_ME_X41 : 6|7@0+ (1,0) [0|127] "" BDY
 SG_ BOH : 6|7@0+ (1,0) [0|127] "" BDY
 SG_ DASHED_LANES : 14|1@0+ (1,0) [0|1] "" BDY
 SG_ DTC : 13|1@0+ (1,0) [0|1] "" BDY
 SG_ LKAS_PROBLEM_MINI_ICON : 12|1@0+ (1,0) [0|0] "" XXX
 SG_ LKAS_OFF : 11|1@0+ (1,0) [0|1] "" BDY
 SG_ SOLID_LANES : 10|1@0+ (1,0) [0|1] "" BDY
 SG_ LANE_DEPARTURE_WARNING : 9|1@0+ (1,0) [0|0] "" XXX
 SG_ STEERING_REQUIRED : 8|1@0+ (1,0) [0|1] "" BDY
 SG_ BOH_2 : 23|2@0+ (1,0) [0|4] "" BDY
 SG_ LDW_PROBLEM : 21|1@0+ (1,0) [0|1] "" BDY
 SG_ BEEP : 17|2@0+ (1,0) [0|1] "" BDY
 SG_ LDW_ON : 28|1@0+ (1,0) [0|1] "" BDY
 SG_ LDW_OFF : 27|1@0+ (1,0) [0|1] "" BDY
 SG_ CLEAN_WINDSHIELD : 26|1@0+ (1,0) [0|1] "" BDY
 SG_ SET_ME_X48 : 31|8@0+ (1,0) [0|255] "" BDY
 SG_ RDM_OFF_MINI_ICON : 22|1@0+ (1,0) [0|0] "" XXX
 SG_ COUNTER : 37|2@0+ (1,0) [0|3] "" BDY
 SG_ CHECKSUM : 35|4@0+ (1,0) [0|15] "" BDY

CM_ SG_ 479 CONTROL_ON "Set to 5 when car is being controlled";
CM_ SG_ 479 AEB_STATUS "set for the duration of AEB event";
CM_ SG_ 479 AEB_BRAKING "set when braking is commanded during AEB event";
CM_ SG_ 479 AEB_PREPARE "set 1s before AEB";
CM_ SG_ 829 BEEP "beeps are pleasant, chimes are for warnngs etc...";

VAL_ 829 BEEP 3 "single_beep" 2 "triple_beep" 1 "repeated_beep" 0 "no_beep";

CM_ "Imported file _steering_sensors_a.dbc starts here";
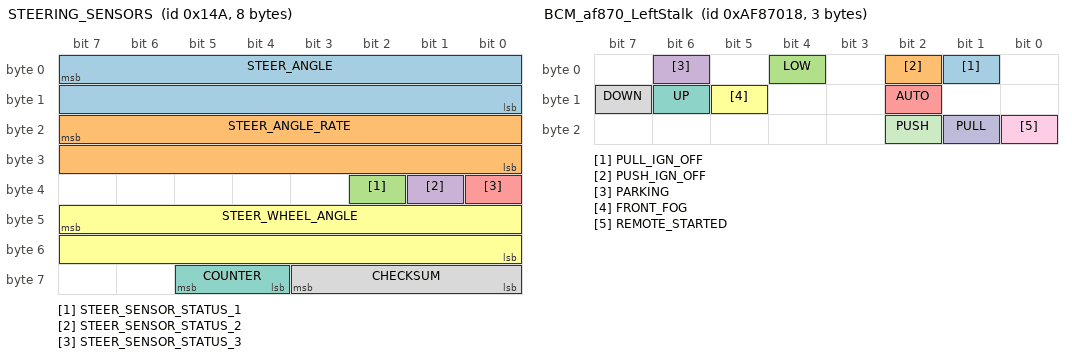
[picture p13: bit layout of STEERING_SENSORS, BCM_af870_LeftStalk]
BO_ 330 STEERING_SENSORS: 8 EPS
 SG_ STEER_ANGLE : 7|16@0- (-0.1,0) [-500|500] "deg" EON
 SG_ STEER_ANGLE_RATE : 23|16@0- (-1,0) [-3000|3000] "deg/s" EON
 SG_ STEER_SENSOR_STATUS_1 : 34|1@0+ (1,0) [0|1] "" EON
 SG_ STEER_SENSOR_STATUS_2 : 33|1@0+ (1,0) [0|1] "" EON
 SG_ STEER_SENSOR_STATUS_3 : 32|1@0+ (1,0) [0|1] "" EON
 SG_ STEER_WHEEL_ANGLE : 47|16@0- (-0.1,0) [-500|500] "deg" EON
 SG_ COUNTER : 61|2@0+ (1,0) [0|3] "" EON
 SG_ CHECKSUM : 59|4@0+ (1,0) [0|15] "" EON

CM_ "Imported file _body_2017.dbc starts here";
CM_ "AUTOGENERATED FILE, DO NOT EDIT";

CM_ "honda_body_2017.dbc starts here";
BO_ 184053784 BCM_af870_LeftStalk: 3 XXX
 SG_ PULL_IGN_OFF : 1|1@0+ (1,0) [0|0] "" XXX
 SG_ PUSH_IGN_OFF : 2|1@0+ (1,0) [0|0] "" XXX
 SG_ LOW : 4|1@0+ (1,0) [0|0] "" XXX
 SG_ PARKING : 6|1@0+ (1,0) [0|0] "" XXX
 SG_ AUTO : 10|1@0+ (1,0) [0|0] "" XXX
 SG_ FRONT_FOG : 13|1@0+ (1,0) [0|0] "" XXX
 SG_ UP : 14|1@0+ (1,0) [0|0] "" XXX
 SG_ DOWN : 15|1@0+ (1,0) [0|0] "" XXX
 SG_ REMOTE_STARTED : 16|1@0+ (1,0) [0|0] "" XXX
 SG_ PULL : 17|1@0+ (1,0) [0|0] "" XXX
 SG_ PUSH : 18|1@0+ (1,0) [0|0] "" XXX

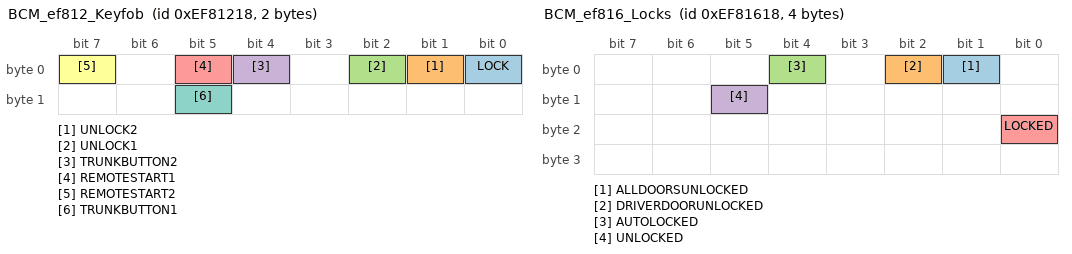
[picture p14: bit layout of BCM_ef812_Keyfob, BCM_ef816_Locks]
BO_ 251138584 BCM_ef812_Keyfob: 2 XXX
 SG_ LOCK : 0|1@0+ (1,0) [0|0] "" XXX
 SG_ UNLOCK2 : 1|1@0+ (1,0) [0|0] "" XXX
 SG_ UNLOCK1 : 2|1@0+ (1,0) [0|0] "" XXX
 SG_ TRUNKBUTTON2 : 4|1@0+ (1,0) [0|0] "" XXX
 SG_ REMOTESTART1 : 5|1@0+ (1,0) [0|0] "" XXX
 SG_ REMOTESTART2 : 7|1@0+ (1,0) [0|0] "" XXX
 SG_ TRUNKBUTTON1 : 13|1@0+ (1,0) [0|0] "" XXX

BO_ 251139096 BCM_ef814_PANIC: 1 XXX
 SG_ PANIC_NOTIFY_3 : 3|1@0+ (1,0) [0|0] "" XXX
 SG_ PANIC_NOTIFY_2 : 5|1@0+ (1,0) [0|0] "" XXX
 SG_ PANIC_NOTIFY_1 : 6|1@0+ (1,0) [0|0] "" XXX
 SG_ PANIC_TRIGGERED : 7|1@0+ (1,0) [0|0] "" XXX

BO_ 251139352 BCM_ef815_ALARM: 1 XXX
 SG_ ALARM_NOTIFY_1 : 3|1@0+ (1,0) [0|0] "" XXX
 SG_ ALARM_NOTIFY_2 : 5|1@0+ (1,0) [0|0] "" XXX
 SG_ ALARM_NOTIFY_3 : 6|1@0+ (1,0) [0|0] "" XXX
 SG_ ALARM_TRIGGERED : 7|1@0+ (1,0) [0|0] "" XXX

BO_ 251139608 BCM_ef816_Locks: 4 XXX
 SG_ ALLDOORSUNLOCKED : 1|1@0+ (1,0) [0|0] "" XXX
 SG_ DRIVERDOORUNLOCKED : 2|1@0+ (1,0) [0|0] "" XXX
 SG_ AUTOLOCKED : 4|1@0+ (1,0) [0|0] "" XXX
 SG_ UNLOCKED : 13|1@0+ (1,0) [0|0] "" XXX
 SG_ LOCKED : 16|1@0+ (1,0) [0|0] "" XXX

BO_ 251163506 Solar_ef873: 6 XXX
 SG_ AUTO_LIGHT_DISENGAGED : 2|1@0+ (1,0) [0|0] "" XXX
 SG_ AUTO_LIGHT_ENGAGED_1 : 7|5@0+ (1,0) [0|0] "" XXX
 SG_ PHOTO_CELL_LUX : 14|17@0+ (1,0) [0|0] "" XXX
 SG_ NEW_SIGNAL_4 : 15|1@0+ (1,0) [0|0] "" XXX
 SG_ NEW_SIGNAL_3 : 39|8@0+ (1,0) [0|0] "" XXX
 SG_ NEW_SIGNAL_1 : 47|6@0+ (1,0) [0|0] "" XXX

BO_ 318246936 BCM_12f810_Lighting: 6 XXX
 SG_ NEW_SIGNAL_6 : 0|3@1+ (1,0) [0|0] "" XXX
 SG_ SET_TO_1_1 : 3|1@0+ (1,0) [0|0] "" XXX
 SG_ BRAKES : 4|1@0+ (1,0) [0|0] "" XXX
 SG_ SET_TO_1_2 : 5|1@0+ (1,0) [0|0] "" XXX
 SG_ NEW_SIGNAL_7 : 7|2@0+ (1,0) [0|0] "" XXX
 SG_ NEW_SIGNAL_5 : 15|8@0+ (1,0) [0|0] "" XXX
 SG_ NEW_SIGNAL_3 : 18|3@0+ (1,0) [0|0] "" XXX
 SG_ RIGHTSIGNAL : 19|1@0+ (1,0) [0|0] "" XXX
 SG_ LEFTSIGNAL : 20|1@0+ (1,0) [0|0] "" XXX
 SG_ HAZARDS_ENABLE : 21|1@0+ (1,0) [0|0] "" XXX
 SG_ NEW_SIGNAL_4 : 22|1@0+ (1,0) [0|0] "" XXX
 SG_ SET_TO_1_3 : 23|1@0+ (1,0) [0|0] "" XXX
 SG_ NEW_SIGNAL_2 : 30|7@0+ (1,0) [0|0] "" XXX
 SG_ REVERSE : 31|1@0+ (1,0) [0|0] "" XXX
 SG_ NEW_SIGNAL_1 : 37|6@0+ (1,0) [0|0] "" XXX
 SG_ AUTORIGHT : 38|1@0+ (1,0) [0|0] "" XXX
 SG_ AUTOLEFT : 39|1@0+ (1,0) [0|0] "" XXX
 SG_ SET_TO_C0 : 47|8@0+ (1,0) [0|0] "" XXX

BO_ 318255128 BCM_12f830_LeftDoors: 1 XXX
 SG_ SET_TO_0_2 : 4|5@0+ (1,0) [0|0] "" XXX
 SG_ LR_OPEN : 5|1@0+ (1,0) [0|0] "" XXX
 SG_ SET_TO_0_1 : 6|1@0+ (1,0) [0|0] "" XXX
 SG_ LF_OPEN : 7|1@0+ (1,0) [0|0] "" XXX

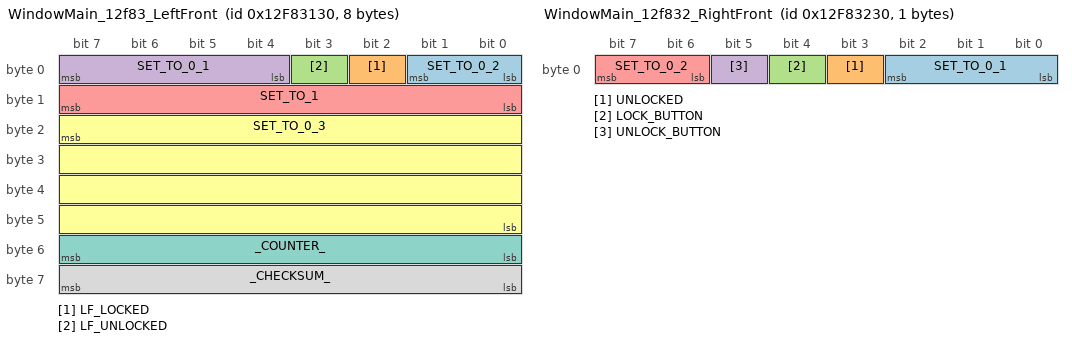
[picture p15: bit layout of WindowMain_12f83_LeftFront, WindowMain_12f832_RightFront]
BO_ 318255408 WindowMain_12f83_LeftFront: 8 XXX
 SG_ SET_TO_0_2 : 0|2@1+ (1,0) [0|0] "" XXX
 SG_ LF_LOCKED : 2|1@0+ (1,0) [0|0] "" XXX
 SG_ LF_UNLOCKED : 3|1@0+ (1,0) [0|0] "" XXX
 SG_ SET_TO_0_1 : 7|4@0+ (1,0) [0|0] "" XXX
 SG_ SET_TO_1 : 15|8@0+ (1,0) [0|0] "" XXX
 SG_ SET_TO_0_3 : 23|32@0+ (1,0) [0|0] "" XXX
 SG_ _COUNTER_ : 48|8@1+ (1,0) [0|0] "" XXX
 SG_ _CHECKSUM_ : 56|8@1+ (1,0) [0|0] "" XXX

BO_ 318255664 WindowMain_12f832_RightFront: 1 XXX
 SG_ SET_TO_0_1 : 0|3@1+ (1,0) [0|0] "" XXX
 SG_ UNLOCKED : 3|1@0+ (1,0) [0|0] "" XXX
 SG_ LOCK_BUTTON : 4|1@0+ (1,0) [0|0] "" XXX
 SG_ UNLOCK_BUTTON : 5|1@0+ (1,0) [0|0] "" XXX
 SG_ SET_TO_0_2 : 7|2@0+ (1,0) [0|0] "" XXX

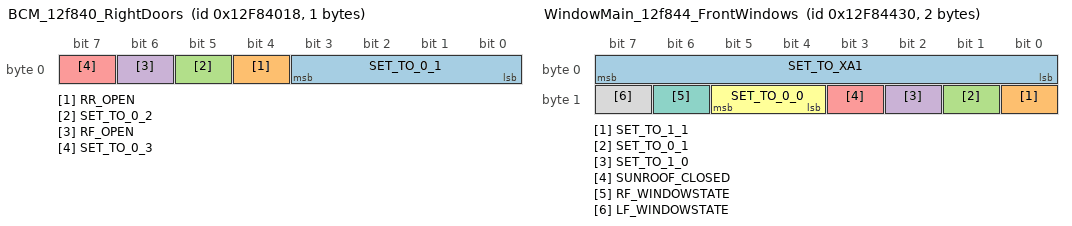
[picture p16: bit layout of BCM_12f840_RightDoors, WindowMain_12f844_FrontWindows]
BO_ 318259224 BCM_12f840_RightDoors: 1 XXX
 SG_ SET_TO_0_1 : 3|4@0+ (1,0) [0|0] "" XXX
 SG_ RR_OPEN : 4|1@0+ (1,0) [0|0] "" XXX
 SG_ SET_TO_0_2 : 5|1@0+ (1,0) [0|0] "" XXX
 SG_ RF_OPEN : 6|1@0+ (1,0) [0|0] "" XXX
 SG_ SET_TO_0_3 : 7|1@0+ (1,0) [0|0] "" XXX

BO_ 318259480 BCM_12f841_LeftRear: 1 XXX
 SG_ SET_TO_0_1 : 6|7@0+ (1,0) [0|0] "" XXX
 SG_ UNLOCKED : 7|1@0+ (1,0) [0|0] "" XXX

BO_ 318259736 BCM_12f842_RightRear: 1 XXX
 SG_ SET_TO_0_1 : 6|7@0+ (1,0) [0|0] "" XXX
 SG_ UNLOCKED : 7|1@0+ (1,0) [0|0] "" XXX

BO_ 318259992 BCM_12f843_Trunk: 1 XXX
 SG_ SET_TO_0_1 : 6|7@0+ (1,0) [0|0] "" XXX
 SG_ TRUNK_OPEN : 7|1@0+ (1,0) [0|0] "" XXX

BO_ 318260272 WindowMain_12f844_FrontWindows: 2 XXX
 SG_ SET_TO_XA1 : 7|8@0+ (1,0) [0|0] "" XXX
 SG_ SET_TO_1_1 : 8|1@0+ (1,0) [0|0] "" XXX
 SG_ SET_TO_0_1 : 9|1@0+ (1,0) [0|0] "" XXX
 SG_ SET_TO_1_0 : 10|1@0+ (1,0) [0|0] "" XXX
 SG_ SUNROOF_CLOSED : 11|1@0+ (1,0) [0|0] "" XXX
 SG_ SET_TO_0_0 : 13|2@0+ (1,0) [0|0] "" XXX
 SG_ RF_WINDOWSTATE : 14|1@0+ (1,0) [0|0] "" XXX
 SG_ LF_WINDOWSTATE : 15|1@0+ (1,0) [0|0] "" XXX

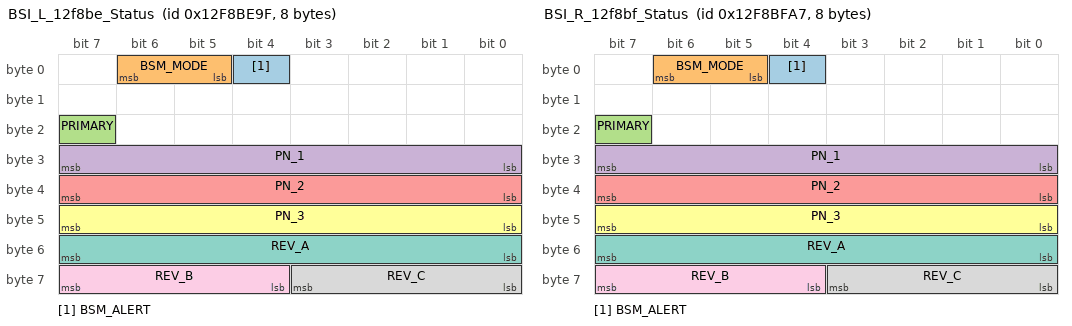
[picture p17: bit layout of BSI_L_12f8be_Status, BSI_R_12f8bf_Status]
BO_ 318291615 BSI_L_12f8be_Status: 8 XXX
 SG_ BSM_ALERT : 4|1@0+ (1,0) [0|0] "" XXX
 SG_ BSM_MODE : 6|2@0+ (1,0) [0|0] "" XXX
 SG_ PRIMARY : 23|1@0+ (1,0) [0|0] "" XXX
 SG_ PN_1 : 31|8@0+ (1,0) [0|0] "" XXX
 SG_ PN_2 : 39|8@0+ (1,0) [0|0] "" XXX
 SG_ PN_3 : 47|8@0+ (1,0) [0|0] "" XXX
 SG_ REV_A : 55|8@0+ (1,0) [0|0] "" XXX
 SG_ REV_C : 59|4@0+ (1,0) [0|0] "" XXX
 SG_ REV_B : 63|4@0+ (1,0) [0|0] "" XXX

BO_ 318291879 BSI_R_12f8bf_Status: 8 XXX
 SG_ BSM_ALERT : 4|1@0+ (1,0) [0|0] "" XXX
 SG_ BSM_MODE : 6|2@0+ (1,0) [0|0] "" XXX
 SG_ PRIMARY : 23|1@0+ (1,0) [0|0] "" XXX
 SG_ PN_1 : 31|8@0+ (1,0) [0|0] "" XXX
 SG_ PN_2 : 39|8@0+ (1,0) [0|0] "" XXX
 SG_ PN_3 : 47|8@0+ (1,0) [0|0] "" XXX
 SG_ REV_A : 55|8@0+ (1,0) [0|0] "" XXX
 SG_ REV_C : 59|4@0+ (1,0) [0|0] "" XXX
 SG_ REV_B : 63|4@0+ (1,0) [0|0] "" XXX

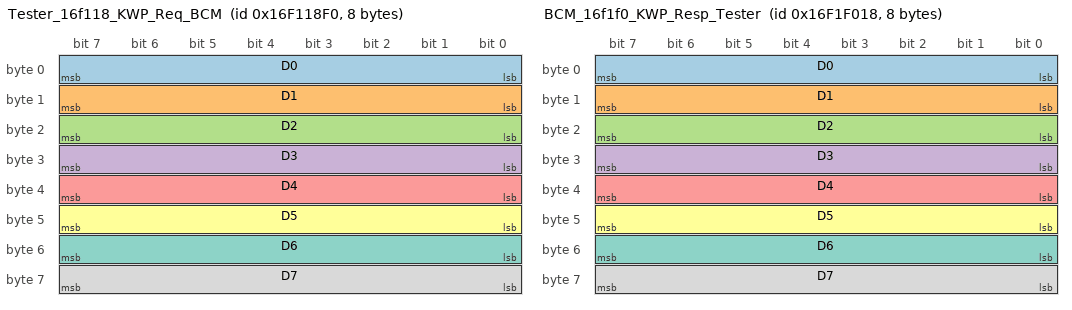
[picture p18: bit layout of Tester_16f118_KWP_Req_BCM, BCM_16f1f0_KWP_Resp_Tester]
BO_ 384899312 Tester_16f118_KWP_Req_BCM: 8 XXX
 SG_ D0 : 7|8@0+ (1,0) [0|0] "" XXX
 SG_ D1 : 15|8@0+ (1,0) [0|0] "" XXX
 SG_ D2 : 23|8@0+ (1,0) [0|0] "" XXX
 SG_ D3 : 31|8@0+ (1,0) [0|0] "" XXX
 SG_ D4 : 39|8@0+ (1,0) [0|0] "" XXX
 SG_ D5 : 47|8@0+ (1,0) [0|0] "" XXX
 SG_ D6 : 55|8@0+ (1,0) [0|0] "" XXX
 SG_ D7 : 63|8@0+ (1,0) [0|0] "" XXX

BO_ 384954392 BCM_16f1f0_KWP_Resp_Tester: 8 XXX
 SG_ D0 : 7|8@0+ (1,0) [0|0] "" XXX
 SG_ D1 : 15|8@0+ (1,0) [0|0] "" XXX
 SG_ D2 : 23|8@0+ (1,0) [0|0] "" XXX
 SG_ D3 : 31|8@0+ (1,0) [0|0] "" XXX
 SG_ D4 : 39|8@0+ (1,0) [0|0] "" XXX
 SG_ D5 : 47|8@0+ (1,0) [0|0] "" XXX
 SG_ D6 : 55|8@0+ (1,0) [0|0] "" XXX
 SG_ D7 : 63|8@0+ (1,0) [0|0] "" XXX

 VAL_ 384954392 D0 127 "UNSUPPORTED" 112 "START_ACCEPTED" 96 "STOP_ACCEPTED" ;
CM_ "honda_accord_2018_can.dbc starts here";

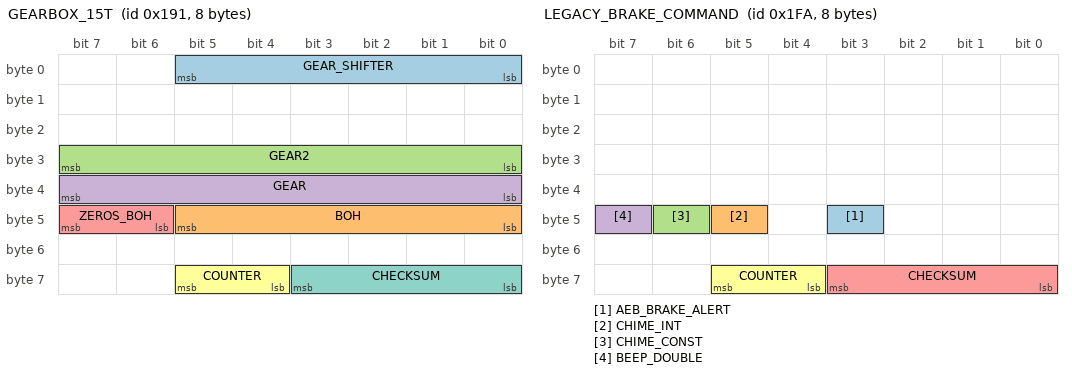
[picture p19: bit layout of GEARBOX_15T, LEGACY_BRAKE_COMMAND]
BO_ 401 GEARBOX_15T: 8 PCM
 SG_ GEAR_SHIFTER : 5|6@0+ (1,0) [0|63] "" EON
 SG_ BOH : 45|6@0+ (1,0) [0|63] "" XXX
 SG_ GEAR2 : 31|8@0+ (1,0) [0|1] "" XXX
 SG_ GEAR : 39|8@0+ (1,0) [0|255] "" XXX
 SG_ ZEROS_BOH : 47|2@0+ (1,0) [0|3] "" XXX
 SG_ COUNTER : 61|2@0+ (1,0) [0|3] "" EON
 SG_ CHECKSUM : 59|4@0+ (1,0) [0|15] "" EON

BO_ 419 GEARBOX: 8 XXX
 SG_ GEAR_SHIFTER : 24|8@1+ (1,0) [0|255] "" XXX
 SG_ GEAR : 32|8@1+ (1,0) [0|255] "" XXX
 SG_ COUNTER : 61|2@0+ (1,0) [0|3] "" XXX
 SG_ CHECKSUM : 59|4@0+ (1,0) [0|15] "" XXX

BO_ 432 STANDSTILL: 7 VSA
 SG_ WHEELS_MOVING : 12|1@0+ (1,0) [0|1] "" EON
 SG_ BRAKE_ERROR_1 : 11|1@0+ (1,0) [0|1] "" EON
 SG_ BRAKE_ERROR_2 : 9|1@0+ (1,0) [0|1] "" EON
 SG_ COUNTER : 53|2@0+ (1,0) [0|3] "" EON
 SG_ CHECKSUM : 51|4@0+ (1,0) [0|15] "" EON

BO_ 446 BRAKE_MODULE: 3 VSA
 SG_ BRAKE_PRESSED : 4|1@0+ (1,0) [0|1] "" XXX
 SG_ COUNTER : 21|2@0+ (1,0) [0|3] "" XXX
 SG_ CHECKSUM : 19|4@0+ (1,0) [0|15] "" XXX

BO_ 506 LEGACY_BRAKE_COMMAND: 8 ADAS
 SG_ AEB_BRAKE_ALERT : 43|1@1+ (1,0) [0|0] "" XXX
 SG_ CHIME_INT : 45|1@0+ (1,0) [0|1] "" XXX
 SG_ CHIME_CONST : 46|1@0+ (1,0) [0|1] "" XXX
 SG_ BEEP_DOUBLE : 47|1@0+ (1,0) [0|1] "" XXX
 SG_ CHECKSUM : 59|4@0+ (1,0) [0|0] "" XXX
 SG_ COUNTER : 61|2@0+ (1,0) [0|0] "" XXX

BO_ 892 CRUISE_PARAMS: 8 PCM
 SG_ CRUISE_SPEED_OFFSET : 31|8@0- (0.1,0) [-128|127] "kph" EON
 SG_ CHECKSUM : 59|4@0+ (1,0) [0|3] "" EON
 SG_ COUNTER : 61|2@0+ (1,0) [0|15] "" EON

BO_ 1302 ODOMETER: 8 XXX
 SG_ ODOMETER : 7|24@0+ (1,0) [0|16777215] "km" EON
 SG_ COUNTER : 61|2@0+ (1,0) [0|3] "" EON
 SG_ CHECKSUM : 59|4@0+ (1,0) [0|3] "" EON

VAL_ 401 GEAR_SHIFTER 32 "L" 16 "S" 8 "D" 4 "N" 2 "R" 1 "P";
VAL_ 401 GEAR 7 "L" 10 "S" 4 "D" 3 "N" 2 "R" 1 "P";
VAL_ 419 GEAR_SHIFTER 2 "S" 32 "D" 16 "N" 8 "R" 4 "P";
VAL_ 419 GEAR 26 "S" 20 "D" 19 "N" 18 "R" 17 "P";
VAL_ 545 ECON_ON_2 0 "off" 3 "on";
VAL_ 662 CRUISE_BUTTONS 7 "tbd" 6 "tbd" 5 "tbd" 4 "accel_res" 3 "decel_set" 2 "cancel" 1 "main" 0 "none";
VAL_ 662 CRUISE_SETTING 3 "distance_adj" 2 "tbd" 1 "lkas_button" 0 "none";
VAL_ 806 CMBS_BUTTON 3 "pressed" 0 "released";
